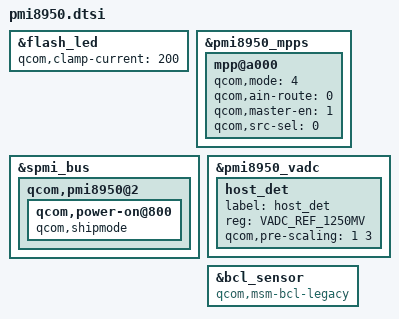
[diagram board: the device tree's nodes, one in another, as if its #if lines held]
&flash_led {
	/delete-property/ qcom,clamp-curr;
	qcom,clamp-current = <200>;
};

&pmi8950_mpps {
	mpp@a000 {
		/* Host detect */
		status = "ok";
		qcom,mode = <4>; /* AIN input */
		qcom,ain-route = <0>; /* AMUX 5 */
		qcom,master-en = <1>;
		qcom,src-sel = <0>; /* Function constant */
	};
};

&spmi_bus {
	qcom,pmi8950@2 {
		qcom,power-on@800 {
			qcom,shipmode;
		};
	};
};

&pmi8950_vadc {
	/delete-node/ ref_1250v;
	host_det {
		label = "host_det";
		reg = <VADC_REF_1250MV>;
		qcom,pre-scaling = <1 3>;
	};
};

#ifdef CONFIG_MSM_BCL_PERIPHERAL_CTL_LEGACY
&bcl_sensor {
	compatible = "qcom,msm-bcl-legacy";
};
#endif
